# ATSAMD51G18A device description
Architecture: CORTEX-M4; Family: SAMD; Series: SAMD51
Registers are 32-bit, read-write, reset 0x0 unless marked. A register's access mark holds for its fields unless they carry their own. Offsets are from the block's base; [hi:lo] are bit positions; {n}, {i} and the like mark numbered series.

## MCLK — Main Clock
Instances: MCLK 0x40000800
0x01 INTENCLR 8-bit (atomic clear) — Interrupt Enable Clear
  [0] CKRDY — Clock Ready Interrupt Enable
0x02 INTENSET 8-bit (atomic set) — Interrupt Enable Set
  [0] CKRDY — Clock Ready Interrupt Enable
0x03 INTFLAG 8-bit reset 0x1 (atomic clear) — Interrupt Flag Status and Clear
  [0] CKRDY — Clock Ready
0x04 HSDIV 8-bit ro reset 0x1 — HS Clock Division
  [7:0] DIV — CPU Clock Division Factor
    1=Divide by 1
0x05 CPUDIV 8-bit reset 0x1 — CPU Clock Division
  [7:0] DIV — Low-Power Clock Division Factor
    1=Divide by 1; 2=Divide by 2; 4=Divide by 4; 8=Divide by 8; 16=Divide by 16; 32=Divide by 32; 64=Divide by 64; 128=Divide by 128
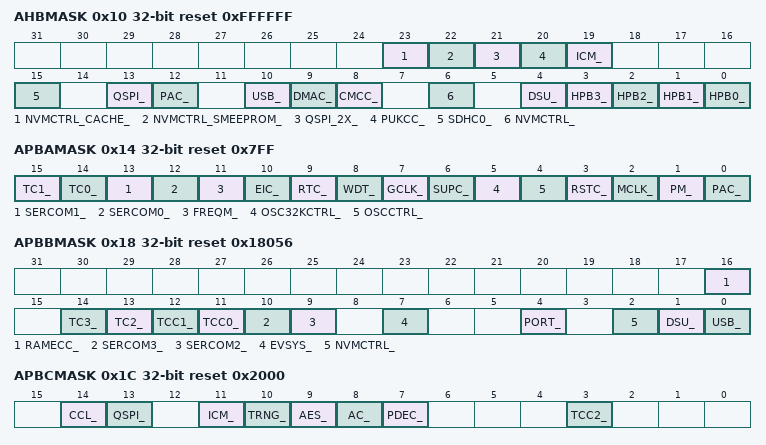
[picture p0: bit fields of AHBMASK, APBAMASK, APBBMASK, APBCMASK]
0x10 AHBMASK reset 0xFFFFFF
  [23] NVMCTRL_CACHE_ — NVMCTRL_CACHE AHB Clock Mask
  [22] NVMCTRL_SMEEPROM_ — NVMCTRL_SMEEPROM AHB Clock Mask
  [21] QSPI_2X_ — QSPI_2X AHB Clock Mask
  [20] PUKCC_ — PUKCC AHB Clock Mask
  [19] ICM_ — ICM AHB Clock Mask
  [15] SDHC0_ — SDHC0 AHB Clock Mask
  [13] QSPI_ — QSPI AHB Clock Mask
  [12] PAC_ — PAC AHB Clock Mask
  [10] USB_ — USB AHB Clock Mask
  [9] DMAC_ — DMAC AHB Clock Mask
  [8] CMCC_ — CMCC AHB Clock Mask
  [6] NVMCTRL_ — NVMCTRL AHB Clock Mask
  [4] DSU_ — DSU AHB Clock Mask
  [n] HPB{n}_ (n=0..3) — HPB{n} AHB Clock Mask
0x14 APBAMASK reset 0x7FF
  [15] TC1_ — TC1 APB Clock Enable
  [14] TC0_ — TC0 APB Clock Enable
  [13] SERCOM1_ — SERCOM1 APB Clock Enable
  [12] SERCOM0_ — SERCOM0 APB Clock Enable
  [11] FREQM_ — FREQM APB Clock Enable
  [10] EIC_ — EIC APB Clock Enable
  [9] RTC_ — RTC APB Clock Enable
  [8] WDT_ — WDT APB Clock Enable
  [7] GCLK_ — GCLK APB Clock Enable
  [6] SUPC_ — SUPC APB Clock Enable
  [5] OSC32KCTRL_ — OSC32KCTRL APB Clock Enable
  [4] OSCCTRL_ — OSCCTRL APB Clock Enable
  [3] RSTC_ — RSTC APB Clock Enable
  [2] MCLK_ — MCLK APB Clock Enable
  [1] PM_ — PM APB Clock Enable
  [0] PAC_ — PAC APB Clock Enable
0x18 APBBMASK reset 0x18056
  [16] RAMECC_ — RAMECC APB Clock Enable
  [14] TC3_ — TC3 APB Clock Enable
  [13] TC2_ — TC2 APB Clock Enable
  [12] TCC1_ — TCC1 APB Clock Enable
  [11] TCC0_ — TCC0 APB Clock Enable
  [10] SERCOM3_ — SERCOM3 APB Clock Enable
  [9] SERCOM2_ — SERCOM2 APB Clock Enable
  [7] EVSYS_ — EVSYS APB Clock Enable
  [4] PORT_ — PORT APB Clock Enable
  [2] NVMCTRL_ — NVMCTRL APB Clock Enable
  [1] DSU_ — DSU APB Clock Enable
  [0] USB_ — USB APB Clock Enable
0x1C APBCMASK reset 0x2000
  [14] CCL_ — CCL APB Clock Enable
  [13] QSPI_ — QSPI APB Clock Enable
  [11] ICM_ — ICM APB Clock Enable
  [10] TRNG_ — TRNG APB Clock Enable
  [9] AES_ — AES APB Clock Enable
  [8] AC_ — AC APB Clock Enable
  [7] PDEC_ — PDEC APB Clock Enable
  [3] TCC2_ — TCC2 APB Clock Enable
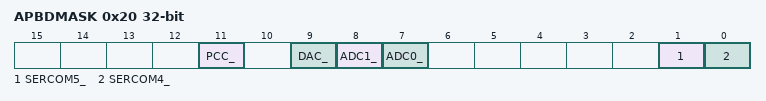
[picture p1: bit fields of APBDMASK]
0x20 APBDMASK
  [11] PCC_ — PCC APB Clock Enable
  [9] DAC_ — DAC APB Clock Enable
  [8] ADC1_ — ADC1 APB Clock Enable
  [7] ADC0_ — ADC0 APB Clock Enable
  [1] SERCOM5_ — SERCOM5 APB Clock Enable
  [0] SERCOM4_ — SERCOM4 APB Clock Enable

## SW0_FUSES — Non-Volatile Fuses
Instances: SW0_FUSES 0x00800080 in fuses
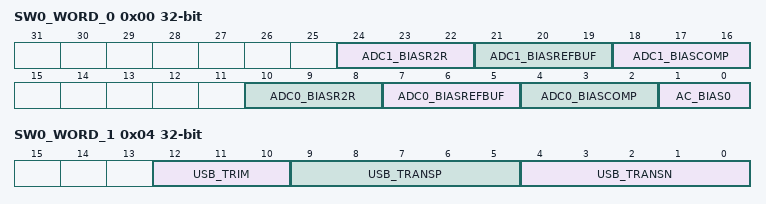
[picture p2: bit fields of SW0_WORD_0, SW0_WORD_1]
0x00 SW0_WORD_0 ro reset not defined — SW0 Page Word 0
  [24:22] ADC1_BIASR2R — ADC Bias R2R ampli scaling
  [21:19] ADC1_BIASREFBUF — ADC Bias Reference Buffer Scaling
  [18:16] ADC1_BIASCOMP — ADC Comparator Scaling
  [10:8] ADC0_BIASR2R — ADC Bias R2R ampli scaling
  [7:5] ADC0_BIASREFBUF — ADC Bias Reference Buffer Scaling
  [4:2] ADC0_BIASCOMP — ADC Comparator Scaling
  [1:0] AC_BIAS0 — PAIR0 Bias Calibration
0x04 SW0_WORD_1 ro reset not defined — SW0 Page Word 1
  [12:10] USB_TRIM — USB pad Trim calibration
  [9:5] USB_TRANSP — USB pad Transp calibration
  [4:0] USB_TRANSN — USB pad Transn calibration

## TEMP_LOG_FUSES — Non-Volatile Fuses
Instances: TEMP_LOG_FUSES 0x00800100 in fuses
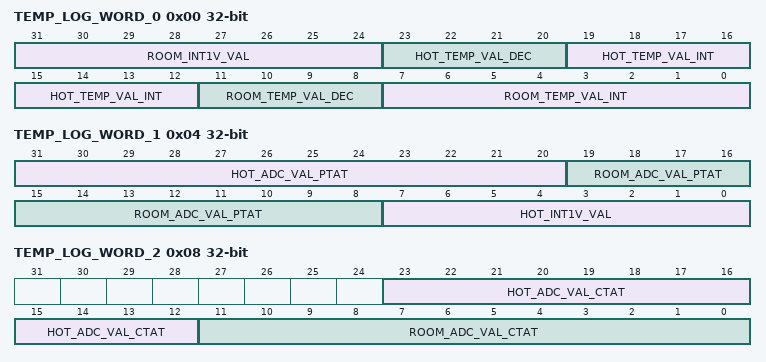
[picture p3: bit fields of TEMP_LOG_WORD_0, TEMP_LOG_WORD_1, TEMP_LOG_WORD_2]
0x00 TEMP_LOG_WORD_0 ro reset not defined — TEMP_LOG Page Word 0
  [31:24] ROOM_INT1V_VAL — 2's complement of the internal 1V reference drift at room temperature (versus a 1.0 centered value)
  [23:20] HOT_TEMP_VAL_DEC — Decimal part of hot temperature
  [19:12] HOT_TEMP_VAL_INT — Integer part of hot temperature in oC
  [11:8] ROOM_TEMP_VAL_DEC — Decimal part of room temperature
  [7:0] ROOM_TEMP_VAL_INT — Integer part of room temperature in oC
0x04 TEMP_LOG_WORD_1 ro reset not defined — TEMP_LOG Page Word 1
  [31:20] HOT_ADC_VAL_PTAT — 12-bit ADC conversion at hot temperature PTAT
  [19:8] ROOM_ADC_VAL_PTAT — 12-bit ADC conversion at room temperature PTAT
  [7:0] HOT_INT1V_VAL — 2's complement of the internal 1V reference drift at hot temperature (versus a 1.0 centered value)
0x08 TEMP_LOG_WORD_2 ro reset not defined — TEMP_LOG Page Word 2
  [23:12] HOT_ADC_VAL_CTAT — 12-bit ADC conversion at hot temperature CTAT
  [11:0] ROOM_ADC_VAL_CTAT — 12-bit ADC conversion at room temperature CTAT

## Notices in the file
Copyright (c) 2021 Microchip Technology Inc.
SPDX-License-Identifier: Apache-2.0
Licensed under the Apache License, Version 2.0 (the "License");
you may not use this file except in compliance with the License.
You may obtain a copy of the License at
http://www.apache.org/licenses/LICENSE-2.0
Unless required by applicable law or agreed to in writing, software
distributed under the License is distributed on an "AS IS" BASIS,
WITHOUT WARRANTIES OR CONDITIONS OF ANY KIND, either express or implied.
See the License for the specific language governing permissions and
limitations under the License.
